AUTOSAR XML (schema 4-2-2)
package /AUTOLIV/SoftwareComponents/PwmIf
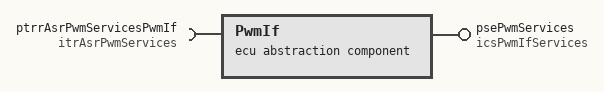
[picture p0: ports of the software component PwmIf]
  ecu abstraction sw component type PwmIf: category=MCAL_IO_Drivers
    provide port psePwmServices: provided-interface=icsPwmIfServices  # # Architecture Element ID ARCH_SW_PwmIf_psePwmServices_PwmIf_SetDutyCycle # Description - The PwmIf_SetDutyCycle runnable shall be called in order set a Pwm Duty Cycle on a uC pin - A configurable array will hold the mapping to Pwm channels(e.g. position 1 of configuration array is Pwm Channel 3). - The runnable will select the Pwm channel from the configuration array with the index from the {Mapped Target Channel Id} input parameter - The runnable will set duty cycle from the {Pwm Duty Cycle} input parameter on the uC pin # Data Flow ## Inputs - {Mapped Target Channel Id} - {Pwm Duty Cycle} #Linked Runnable - PwmIf_SetDutyCycle # Traceability #----------------------------------------------------------------------------------------------------------------------------------------------------- # Architecture Element ID ARCH_SW_PwmIf_psePwmServices_PwmIf_EnablePWM # Description - The PwmIf_EnablePWM runnable shall be called in order to enable Pwm Duty Cycle on a uC pin # Data Flow ## Inputs - {Mapped Target Channel Id} #Linked Runnable - PwmIf_EnablePWM # Traceability #----------------------------------------------------------------------------------------------------------------------------------------------------- # Architecture Element ID ARCH_SW_PwmIf_psePwmServices_PwmIf_DisablePWM # Description - The PwmIf_DisablePWM runnable shall be called in order to disable Pwm Duty Cycle on a uC pin # Data Flow ## Inputs - {Mapped Target Channel Id} #Linked Runnable - PwmIf_DisablePWM # Traceability
      provided-com-specs:
        operation=EnablePWM, queue-length=1
        operation=DisablePWM, queue-length=1
        operation=SetDutyCycle, queue-length=1
    require port ptrrAsrPwmServicesPwmIf: required-interface=itrAsrPwmServices  # # Architecture Element ID ARCH_SW_DioIf_PwmIf_ptrrAsrPwmServicesPwmIf_Pwm_SetDutyCycle_PwmIf_SetDutyCycle # Description - The Pwm_SetDutyCycle runnable shall be called in the PwmIf_SetDutyCycle runnable in order to set a duty cycle on a uC pin # Data Flow ## Inputs - {Target Channel Id} - {Pwm Duty Cycle} ## Outptus #Linked Runnable - PwmIf_SetDutyCycle # Traceability
